// ============== CAN Bus Protocol v0.0.1 ==============

VERSION ""

NS_ :

BS_:

BU_: OBC EPS ADCS

// ============== OBC (0x001 - 0x0FF) ==============

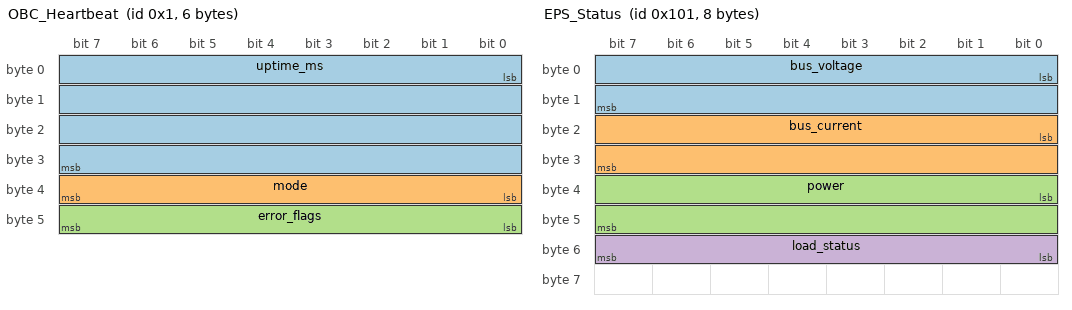
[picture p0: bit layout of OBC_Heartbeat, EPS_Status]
BO_ 1 OBC_Heartbeat: 6 OBC
  SG_ uptime_ms : 0|32@1+ (1,0) [0|4294967295] "ms" ADCS,EPS
  SG_ mode : 32|8@1+ (1,0) [0|255] "" ADCS,EPS
  SG_ error_flags : 40|8@1+ (1,0) [0|255] "" ADCS,EPS

BO_ 2 OBC_Mode_Cmd: 1 OBC
  SG_ mode : 0|8@1+ (1,0) [0|255] "" ADCS,EPS

BO_ 3 OBC_EPS_Cmd: 1 OBC
  SG_ command : 0|8@1+ (1,0) [0|255] "" EPS

BO_ 4 OBC_ADCS_Cmd: 1 OBC
  SG_ command : 0|8@1+ (1,0) [0|255] "" ADCS

// ============== EPS (0x100 - 0x1FF) ==============

BO_ 256 EPS_Heartbeat: 5 EPS
  SG_ uptime_ms : 0|32@1+ (1,0) [0|4294967295] "ms" OBC
  SG_ error_flags : 32|8@1+ (1,0) [0|255] "" OBC

BO_ 257 EPS_Status: 8 EPS
  SG_ bus_voltage : 0|16@1+ (0.01,0) [0|655.35] "V" OBC
  SG_ bus_current : 16|16@1+ (0.01,0) [0|655.35] "A" OBC
  SG_ power : 32|16@1+ (0.1,0) [0|6553.5] "W" OBC
  SG_ load_status : 48|8@1+ (1,0) [0|255] "" OBC

// ============== ADCS Actuators (0x200 - 0x2FF) ==============

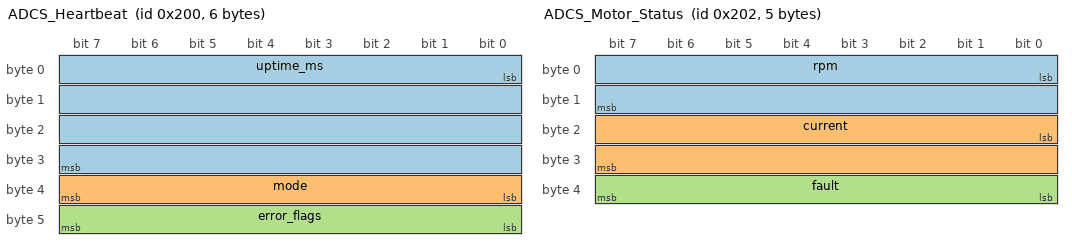
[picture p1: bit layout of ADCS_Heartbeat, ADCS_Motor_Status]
BO_ 512 ADCS_Heartbeat: 6 ADCS
  SG_ uptime_ms : 0|32@1+ (1,0) [0|4294967295] "ms" OBC
  SG_ mode : 32|8@1+ (1,0) [0|255] "" OBC
  SG_ error_flags : 40|8@1+ (1,0) [0|255] "" OBC

BO_ 513 ADCS_Motor_Cmd: 3 OBC
  SG_ duty_cycle : 0|16@1+ (1,0) [0|65535] "" ADCS
  SG_ enable : 16|8@1+ (1,0) [0|1] "" ADCS

BO_ 514 ADCS_Motor_Status: 5 ADCS
  SG_ rpm : 0|16@1+ (1,0) [0|65535] "rpm" OBC
  SG_ current : 16|16@1+ (0.01,0) [0|655.35] "A" OBC
  SG_ fault : 32|8@1+ (1,0) [0|255] "" OBC

// ============== ADCS Sensors (0x300 - 0x3FF) ==============

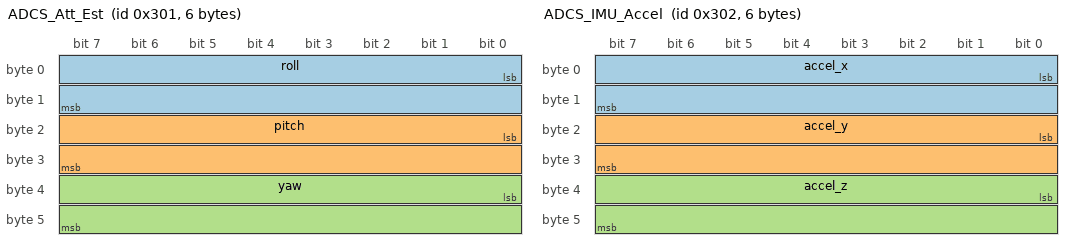
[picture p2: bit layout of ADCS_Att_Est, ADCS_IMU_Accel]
BO_ 769 ADCS_Att_Est: 6 ADCS
  SG_ roll : 0|16@1- (0.1,0) [-3276.8|3276.7] "deg/s" OBC
  SG_ pitch : 16|16@1- (0.1,0) [-3276.8|3276.7] "deg/s" OBC
  SG_ yaw : 32|16@1- (0.1,0) [-3276.8|3276.7] "deg/s" OBC

BO_ 770 ADCS_IMU_Accel: 6 ADCS
  SG_ accel_x : 0|16@1- (0.01,0) [-327.68|327.67] "m/s2" OBC
  SG_ accel_y : 16|16@1- (0.01,0) [-327.68|327.67] "m/s2" OBC
  SG_ accel_z : 32|16@1- (0.01,0) [-327.68|327.67] "m/s2" OBC

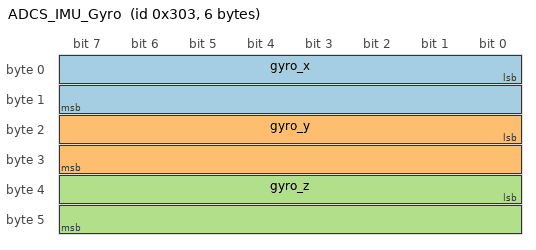
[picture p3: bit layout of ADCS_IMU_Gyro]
BO_ 771 ADCS_IMU_Gyro: 6 ADCS
  SG_ gyro_x : 0|16@1- (0.1,0) [-3276.8|3276.7] "deg/s" OBC
  SG_ gyro_y : 16|16@1- (0.1,0) [-3276.8|3276.7] "deg/s" OBC
  SG_ gyro_z : 32|16@1- (0.1,0) [-3276.8|3276.7] "deg/s" OBC
